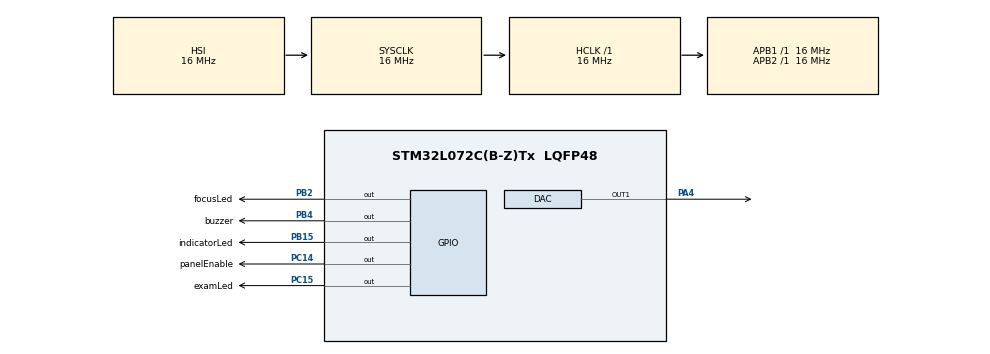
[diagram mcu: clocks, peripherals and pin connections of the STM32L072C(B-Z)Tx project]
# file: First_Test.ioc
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Mcu.Family=STM32L0
Mcu.Name=STM32L072C(B-Z)Tx
Mcu.Package=LQFP48
PA13.Mode=Serial_Wire
PA13.Signal=SYS_SWDIO
PA14.Mode=Serial_Wire
PA14.Signal=SYS_SWCLK
PA4.Signal=COMP_DAC1_group
PB15.GPIO_Label=indicatorLed
PB15.Signal=GPIO_Output
PB2.GPIO_Label=focusLed
PB2.Signal=GPIO_Output
PB4.GPIO_Label=buzzer
PB4.Signal=GPIO_Output
PC14-OSC32_IN.GPIO_Label=panelEnable
PC14-OSC32_IN.Signal=GPIO_Output
PC15-OSC32_OUT.GPIO_Label=examLed
PC15-OSC32_OUT.Signal=GPIO_Output
ProjectManager.HeapSize=0x200
ProjectManager.StackSize=0x400
ProjectManager.TargetToolchain=MDK-ARM V5
RCC.AHBFreq_Value=16000000
RCC.APB1Freq_Value=16000000
RCC.APB1TimFreq_Value=16000000
RCC.APB2Freq_Value=16000000
RCC.APB2TimFreq_Value=16000000
RCC.HCLKFreq_Value=16000000
RCC.HSE_VALUE=8000000
RCC.HSI16_VALUE=16000000
RCC.HSI48_VALUE=48000000
RCC.HSI_VALUE=16000000
RCC.LSE_VALUE=32768
RCC.MSI_VALUE=2097000
RCC.SYSCLKFreq_VALUE=16000000
RCC.SYSCLKSource=RCC_SYSCLKSOURCE_HSI
RCC.VCOOutputFreq_Value=48000000
SH.COMP_DAC1_group.0=DAC_OUT1,DAC_OUT1
board=custom

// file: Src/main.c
/* USER CODE BEGIN Header */
/**
  ******************************************************************************
  * @file           : main.c
  * @brief          : Main program body
  ******************************************************************************
  * @attention
  *
  * <h2><center>&copy; Copyright (c) 2021 STMicroelectronics.
  * All rights reserved.</center></h2>
  *
  * This software component is licensed by ST under BSD 3-Clause license,
  * the "License"; You may not use this file except in compliance with the
  * License. You may obtain a copy of the License at:
  *                        opensource.org/licenses/BSD-3-Clause
  *
  ******************************************************************************
  */
/* USER CODE END Header */

#include "main.h"

DAC_HandleTypeDef hdac;

/* USER CODE BEGIN PV */
int level=0;
/* USER CODE END PV */

void SystemClock_Config(void);
static void MX_GPIO_Init(void);
static void MX_DAC_Init(void);

int main(void)
{

  /* MCU Configuration--------------------------------------------------------*/

  /* Reset of all peripherals, Initializes the Flash interface and the Systick. */
  HAL_Init();

  /* Configure the system clock */
  SystemClock_Config();

  /* Initialize all configured peripherals */
  MX_GPIO_Init();
  MX_DAC_Init();
  /* USER CODE BEGIN 2 */

	HAL_DAC_Start(&hdac, DAC_CHANNEL_1);

  /* USER CODE END 2 */
	HAL_GPIO_WritePin(buzzer_GPIO_Port, buzzer_Pin, GPIO_PIN_SET);
	HAL_Delay(100);
	HAL_GPIO_WritePin(buzzer_GPIO_Port, buzzer_Pin, GPIO_PIN_RESET);
	HAL_Delay(20);
	HAL_GPIO_WritePin(buzzer_GPIO_Port, buzzer_Pin, GPIO_PIN_SET);
	HAL_Delay(80);
	HAL_GPIO_WritePin(buzzer_GPIO_Port, buzzer_Pin, GPIO_PIN_RESET);
	HAL_Delay(20);
	HAL_GPIO_WritePin(buzzer_GPIO_Port, buzzer_Pin, GPIO_PIN_SET);
	HAL_Delay(100);
	HAL_GPIO_WritePin(buzzer_GPIO_Port, buzzer_Pin, GPIO_PIN_RESET);
	HAL_Delay(20);

  /* Infinite loop */
  /* USER CODE BEGIN WHILE */
  while (1)
  {
		HAL_GPIO_TogglePin(indicatorLed_GPIO_Port, indicatorLed_Pin);
		HAL_Delay(100);
    /* USER CODE END WHILE */
		/*HAL_GPIO_WritePin(buzzer_GPIO_Port, buzzer_Pin, GPIO_PIN_SET);
		HAL_Delay(100);
		HAL_GPIO_WritePin(buzzer_GPIO_Port, buzzer_Pin, GPIO_PIN_RESET);
		HAL_Delay(20);
		HAL_GPIO_WritePin(buzzer_GPIO_Port, buzzer_Pin, GPIO_PIN_SET);
		HAL_Delay(80);
		HAL_GPIO_WritePin(buzzer_GPIO_Port, buzzer_Pin, GPIO_PIN_RESET);
		HAL_Delay(20);
		HAL_GPIO_WritePin(buzzer_GPIO_Port, buzzer_Pin, GPIO_PIN_SET);
		HAL_Delay(100);
		HAL_GPIO_WritePin(buzzer_GPIO_Port, buzzer_Pin, GPIO_PIN_RESET);
		HAL_Delay(20);

		HAL_GPIO_WritePin(examLed_GPIO_Port, examLed_Pin, GPIO_PIN_SET);
		HAL_Delay(1000);
		HAL_GPIO_WritePin(examLed_GPIO_Port, examLed_Pin, GPIO_PIN_RESET);
		HAL_Delay(1000);

		HAL_GPIO_WritePin(focusLed_GPIO_Port, focusLed_Pin, GPIO_PIN_SET);
		HAL_Delay(1000);
		HAL_GPIO_WritePin(focusLed_GPIO_Port, focusLed_Pin, GPIO_PIN_RESET);
		HAL_Delay(1000);

		HAL_DAC_SetValue(&hdac, DAC_CHANNEL_1, DAC_ALIGN_12B_R, 0);
		HAL_GPIO_WritePin(panelEnable_GPIO_Port, panelEnable_Pin, GPIO_PIN_SET);
		HAL_Delay(1000);
		HAL_DAC_SetValue(&hdac, DAC_CHANNEL_1, DAC_ALIGN_12B_R, 100);
		HAL_Delay(1000);
		HAL_DAC_SetValue(&hdac, DAC_CHANNEL_1, DAC_ALIGN_12B_R, 200);
		HAL_Delay(3000);
		HAL_DAC_SetValue(&hdac, DAC_CHANNEL_1, DAC_ALIGN_12B_R, 300);
		HAL_Delay(3000);
		HAL_DAC_SetValue(&hdac, DAC_CHANNEL_1, DAC_ALIGN_12B_R, 425);
		HAL_Delay(3000);

		HAL_DAC_SetValue(&hdac, DAC_CHANNEL_1, DAC_ALIGN_12B_R, 0);
		HAL_GPIO_WritePin(panelEnable_GPIO_Port, panelEnable_Pin, GPIO_PIN_RESET);
		HAL_Delay(1000);*/

  }
}

void SystemClock_Config(void)
{
  RCC_OscInitTypeDef RCC_OscInitStruct = {0};
  RCC_ClkInitTypeDef RCC_ClkInitStruct = {0};

  /** Configure the main internal regulator output voltage
  */
  __HAL_PWR_VOLTAGESCALING_CONFIG(PWR_REGULATOR_VOLTAGE_SCALE1);
  /** Initializes the CPU, AHB and APB busses clocks
  */
  RCC_OscInitStruct.OscillatorType = RCC_OSCILLATORTYPE_HSI;
  RCC_OscInitStruct.HSIState = RCC_HSI_ON;
  RCC_OscInitStruct.HSICalibrationValue = RCC_HSICALIBRATION_DEFAULT;
  RCC_OscInitStruct.PLL.PLLState = RCC_PLL_NONE;
  if (HAL_RCC_OscConfig(&RCC_OscInitStruct) != HAL_OK)
  {
    Error_Handler();
  }
  /** Initializes the CPU, AHB and APB busses clocks
  */
  RCC_ClkInitStruct.ClockType = RCC_CLOCKTYPE_HCLK|RCC_CLOCKTYPE_SYSCLK
                              |RCC_CLOCKTYPE_PCLK1|RCC_CLOCKTYPE_PCLK2;
  RCC_ClkInitStruct.SYSCLKSource = RCC_SYSCLKSOURCE_HSI;
  RCC_ClkInitStruct.AHBCLKDivider = RCC_SYSCLK_DIV1;
  RCC_ClkInitStruct.APB1CLKDivider = RCC_HCLK_DIV1;
  RCC_ClkInitStruct.APB2CLKDivider = RCC_HCLK_DIV1;

  if (HAL_RCC_ClockConfig(&RCC_ClkInitStruct, FLASH_LATENCY_0) != HAL_OK)
  {
    Error_Handler();
  }
}

static void MX_DAC_Init(void)
{

  DAC_ChannelConfTypeDef sConfig = {0};

  /** DAC Initialization
  */
  hdac.Instance = DAC;
  if (HAL_DAC_Init(&hdac) != HAL_OK)
  {
    Error_Handler();
  }
  /** DAC channel OUT1 config
  */
  sConfig.DAC_Trigger = DAC_TRIGGER_NONE;
  sConfig.DAC_OutputBuffer = DAC_OUTPUTBUFFER_ENABLE;
  if (HAL_DAC_ConfigChannel(&hdac, &sConfig, DAC_CHANNEL_1) != HAL_OK)
  {
    Error_Handler();
  }

}

static void MX_GPIO_Init(void)
{
  GPIO_InitTypeDef GPIO_InitStruct = {0};

  /* GPIO Ports Clock Enable */
  __HAL_RCC_GPIOC_CLK_ENABLE();
  __HAL_RCC_GPIOA_CLK_ENABLE();
  __HAL_RCC_GPIOB_CLK_ENABLE();

  /*Configure GPIO pin Output Level */
  HAL_GPIO_WritePin(GPIOC, panelEnable_Pin|examLed_Pin, GPIO_PIN_RESET);

  /*Configure GPIO pin Output Level */
  HAL_GPIO_WritePin(GPIOB, focusLed_Pin|indicatorLed_Pin|buzzer_Pin, GPIO_PIN_RESET);

  /*Configure GPIO pins : panelEnable_Pin examLed_Pin */
  GPIO_InitStruct.Pin = panelEnable_Pin|examLed_Pin;
  GPIO_InitStruct.Mode = GPIO_MODE_OUTPUT_PP;
  GPIO_InitStruct.Pull = GPIO_NOPULL;
  GPIO_InitStruct.Speed = GPIO_SPEED_FREQ_LOW;
  HAL_GPIO_Init(GPIOC, &GPIO_InitStruct);

  /*Configure GPIO pins : focusLed_Pin indicatorLed_Pin buzzer_Pin */
  GPIO_InitStruct.Pin = focusLed_Pin|indicatorLed_Pin|buzzer_Pin;
  GPIO_InitStruct.Mode = GPIO_MODE_OUTPUT_PP;
  GPIO_InitStruct.Pull = GPIO_NOPULL;
  GPIO_InitStruct.Speed = GPIO_SPEED_FREQ_LOW;
  HAL_GPIO_Init(GPIOB, &GPIO_InitStruct);

}

void Error_Handler(void)
{
}

/************************ (C) COPYRIGHT STMicroelectronics *****END OF FILE****/
